# RK3399-AP register map
File version: 1
CPU: CA7 r0p1, little endian, MPU, FPU, I-cache, D-cache, VTOR, 4 interrupt priority bits, 0 interrupts
Registers are 32-bit, read-write, reset 0x0 unless marked. A register's access mark holds for its fields unless they carry their own. Offsets are from the block's base; [hi:lo] are bit positions.

## UART0
Base 0xFF180000
Same registers: UART1 0xFF190000, UART2 0xFF1A0000, UART3 0xFF1B0000, UART4 0xFF370000
0x00 UART_RBR — Receive Buffer Register
  [7:0] DATA_INPUT — Data byte received on the serial input port (sin) in UART mode, or the serial infrared input (sir_in) in infrared mode. The data in this register is valid only if the Data Ready (DR) bit in the Line Status Register (LCR) is set. If in non-FIFO mode (FIFO_MODE == NONE) or FIFOs are disabled (FCR[0] set to zero), the data in the RBR must be read before the next data arrives, otherwise it is overwritten, resulting in an over-run error. If in FIFO mode (FIFO_MODE != NONE) and FIFOs are enabled (FCR[0] set to one), this register accesses the head of the receive FIFO. If the receive FIFO is full and this register is not read before the next data character arrives, then the data already in the FIFO is preserved, but any incoming data are lost and an over-run error occurs.
0x00 UART_THR — Transmit Holding Register
  [7:0] DATA_OUTPUT — Data to be transmitted on the serial output port (sout) in UART mode or the serial infrared output (sir_out_n) in infrared mode. Data should only be written to the THR when the THR Empty (THRE) bit (LSR[5]) is set. If in non-FIFO mode or FIFOs are disabled (FCR[0] = 0) and THRE is set, writing a single character to the THR clears the THRE. Any additional writes to the THR before the THRE is set again causes the THR data to be overwritten. If in FIFO mode and FIFOs are enabled (FCR[0] = 1) and THRE is set, x number of characters of data may be written to the THR before the FIFO is full. The number x (default=16) is determined by the value of FIFO Depth that you set during configuration. Any attempt to write data when the FIFO is full results in the write data being lost.
0x00 UART_DLL — Divisor Latch (Low)
  [7:0] BAUD_RATE_DIVISOR_L — Lower 8-bits of a 16-bit, read/write, Divisor Latch register that contains the baud rate divisor for the UART. This register may only be accessed when the DLAB bit (LCR[7]) is set and the UART is not busy (USR[0] is zero). The output baud rate is equal to the serial clock (sclk) frequency divided by sixteen times the value of the baud rate divisor, as follows: baud rate = (serial clock freq) / (16 * divisor). Note that with the Divisor Latch Registers (DLL and DLH) set to zero, the baud clock is disabled and no serial communications occur. Also, once the DLH is set, at least 8 clock cycles of the slowest UART clock should be allowed to pass before transmitting or receiving data.
0x04 UART_DLH — Divisor Latch (High)
  [7:0] BAUD_RATE_DIVISOR_H — Upper 8 bits of a 16-bit, read/write, Divisor Latch register that contains the baud rate divisor for the UART.
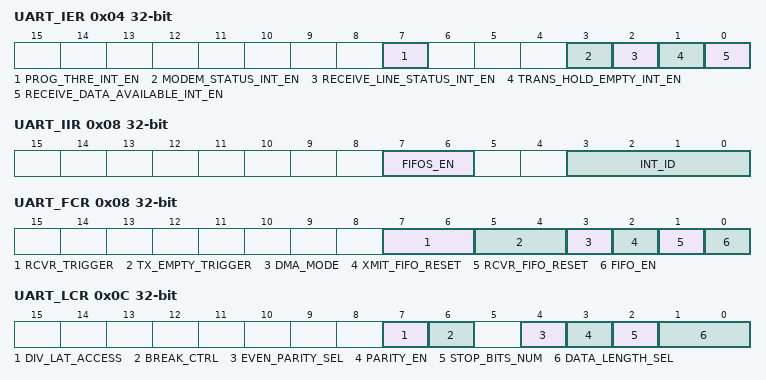
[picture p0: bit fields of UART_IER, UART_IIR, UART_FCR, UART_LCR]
0x04 UART_IER — Interrupt Enable Register
  [7] PROG_THRE_INT_EN — Programmable THRE Interrupt Mode Enable This is used to enable/disable the generation of THRE Interrupt. 0 = disabled 1 = enabled
  [3] MODEM_STATUS_INT_EN — Enable Modem Status Interrupt. This is used to enable/disable the generation of Modem Status Interrupt. This is the fourth highest priority interrupt. 0 = disabled 1 = enabled
  [2] RECEIVE_LINE_STATUS_INT_EN — Enable Receiver Line Status Interrupt. This is used to enable/disable the generation of Receiver Line Status Interrupt. This is the highest priority interrupt. 0 = disabled 1 = enabled
  [1] TRANS_HOLD_EMPTY_INT_EN — Enable Transmit Holding Register Empty Interrupt.
  [0] RECEIVE_DATA_AVAILABLE_INT_EN — Enable Received Data Available Interrupt. This is used to enable/disable the generation of Received Data Available Interrupt and the Character Timeout Interrupt (if in FIFO mode and FIFOs enabled). These are the second highest priority interrupts. 0 = disabled 1 = enabled
0x08 UART_IIR ro — Interrupt Identification Register
  [7:6] FIFOS_EN — FIFOs Enabled. This is used to indicate whether the FIFOs are enabled or disabled. 00 = disabled 11 = enabled
  [3:0] INT_ID — Interrupt ID This indicates the highest priority pending interrupt which can be one of the following types: 0000 = modem status 0001 = no interrupt pending 0010 = THR empty 0100 = received data available 0110 = receiver line status 0111 = busy detect 1100 = character timeout
0x08 UART_FCR wo — FIFO Control Register
  [7:6] RCVR_TRIGGER — RCVR Trigger. This is used to select the trigger level in the receiver FIFO at which the Received Data Available Interrupt is generated. In auto flow control mode it is used to determine when the rts_n signal is de-asserted. It also determines when the dma_rx_req_n signal is asserted in certain modes of operation. The following trigger levels are supported: 00 = 1 character in the FIFO 01 = FIFO 1/4 full 10 = FIFO 1/2 full 11 = FIFO 2 less than ful
  [5:4] TX_EMPTY_TRIGGER — TX Empty Trigger. This is used to select the empty threshold level at which the THRE Interrupts are generated when the mode is active. It also determines when the dma_tx_req_n signal is asserted when in certain modes of operation. The following trigger levels are supported: 00 = FIFO empty 01 = 2 characters in the FIFO 10 = FIFO 1/4 full 11 = FIFO 1/2 full
  [3] DMA_MODE — DMA Mode This determines the DMA signalling mode used for the dma_tx_req_n and dma_rx_req_n output signals when additional DMA handshaking signals are not selected . 0 = mode 0 1 = mode 11100 = character timeout.
  [2] XMIT_FIFO_RESET — XMIT FIFO Reset. This resets the control portion of the transmit FIFO and treats the FIFO as empty. This also de-asserts the DMA TX request and single signals when additional DMA handshaking signals are selected . Note that this bit is \'self-clearing\'. It is not necessary to clear this bit.
  [1] RCVR_FIFO_RESET — RCVR FIFO Reset. This resets the control portion of the receive FIFO and treats the FIFO as empty. This also de-asserts the DMA RX request and single signals when additional DMA handshaking signals are selected. Note that this bit is \'self-clearing\'. It is not necessary to clear this bit.
  [0] FIFO_EN — FIFO Enable. FIFO Enable. This enables/disables the transmit (XMIT) and receive (RCVR) FIFOs. Whenever the value of this bit is changed both the XMIT and RCVR controller portion of FIFOs is reset.
0x0C UART_LCR — Line Control Register
  [7] DIV_LAT_ACCESS — Divisor Latch Access Bit. Writeable only when UART is not busy (USR[0] is zero), always readable. This bit is used to enable reading and writing of the Divisor Latch register (DLL and DLH) to set the baud rate of the UART. This bit must be cleared after initial baud rate setup in order to access other registers.
  [6] BREAK_CTRL — Break Control Bit. This is used to cause a break condition to be transmitted to the receiving device. If set to one the serial output is forced to the spacing (logic 0) state. When not in Loopback Mode, as determined by MCR[4], the sout line is forced low until the Break bit is cleared. If MCR[6] set to one, the sir_out_n line is continuously pulsed. When in Loopback Mode, the break condition is internally looped back to the receiver and the sir_out_n line is forced low.
  [4] EVEN_PARITY_SEL — Even Parity Select. Writeable only when UART is not busy (USR[0] is zero), always readable. This is used to select between even and odd parity, when parity is enabled (PEN set to one). If set to one, an even number of logic 1s is transmitted or checked. If set to zero, an odd number of logic 1s is transmitted or checked.
  [3] PARITY_EN — Parity Enable. Writeable only when UART is not busy (USR[0] is zero), always readable. This bit is used to enable and disable parity generation and detection in transmitted and received serial character respectively. 0 = parity disabled 1 = parity enabled
  [2] STOP_BITS_NUM — Number of stop bits. Writeable only when UART is not busy (USR[0] is zero), always readable. This is used to select the number of stop bits per character that the peripheral transmits and receives. If set to zero, one stop bit is transmitted in the serial data. If set to one and the data bits are set to 5 (LCR[1:0] set to zero) one and a half stop bits is transmitted. Otherwise, two stop bits are transmitted. Note that regardless of the number of stop bits selected, the receiver checks only the first stop bit. 0 = 1 stop bit 1 = 1.5 stop bits when DLS (LCR[1:0]) is zero, else 2 stop bit.
  [1:0] DATA_LENGTH_SEL — Data Length Select. Writeable only when UART is not busy (USR[0] is zero), always readable. This is used to select the number of data bits per character that the peripheral transmits and receives. The number of bit that may be selected areas follows: 00 = 5 bits 01 = 6 bits 10 = 7 bits 11 = 8 bits
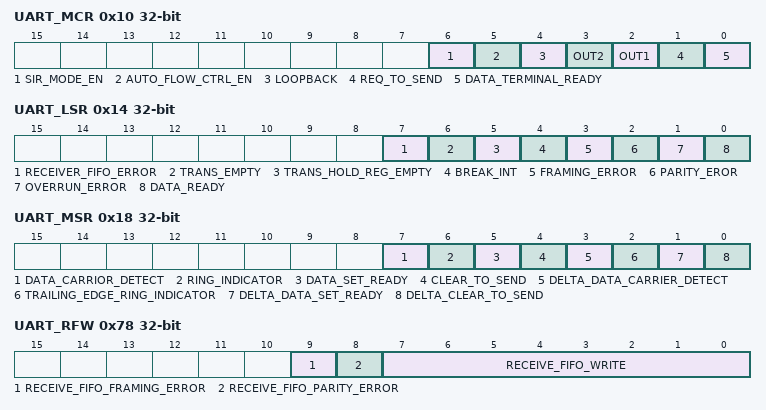
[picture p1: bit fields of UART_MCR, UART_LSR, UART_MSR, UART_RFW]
0x10 UART_MCR — Modem Control Register
  [6] SIR_MODE_EN — SIR Mode Enable. SIR Mode Enable. This is used to enable/disable the IrDA SIR Mode . 0 = IrDA SIR Mode disabled 1 = IrDA SIR Mode enabled
  [5] AUTO_FLOW_CTRL_EN — Auto Flow Control Enable. 0 = Auto Flow Control Mode disabled 1 = Auto Flow Control Mode enabled
  [4] LOOPBACK — LoopBack Bit. This is used to put the UART into a diagnostic mode for test purposes.
  [3] OUT2 — OUT2. This is used to directly control the user-designated Output2 (out2_n) output. The value written to this location is inverted and driven out on out2_n, that is: 0 = out2_n de-asserted (logic 1) 1 = out2_n asserted (logic 0)
  [2] OUT1 — OUT1 This is used to directly control the user-designated Output2 (out2_n) output. The value written to this location is inverted and driven out on out2_n, that is: 1’b0: out2_n de-asserted (logic 1) 1’b1: out2_n asserted (logic 0) req_to_send Request to Send. This is used to directly control the Request to Send (rts_n) output. The Request To Send (rts_n) output is used to inform the modem or data set that the UART is ready to exchange data.
  [1] REQ_TO_SEND — Request to Send. This is used to directly control the Request to Send (rts_n) output. The Request To Send (rts_n) output is used to inform the modem or data set that the UART is ready to exchange data.
  [0] DATA_TERMINAL_READY — Data Terminal Ready. This is used to directly control the Data Terminal Ready (dtr_n) output. The value written to this location is inverted and driven out on dtr_n, that is: 0 = dtr_n de-asserted (logic 1) 1 = dtr_n asserted (logic 0)
0x14 UART_LSR ro — Line Status Register
  [7] RECEIVER_FIFO_ERROR — Receiver FIFO Error bit. This bit is relevant FIFOs are enabled (FCR[0] set to one). This is used to indicate if there is at least one parity error, framing error, or break indication in the FIFO. 0 = no error in RX FIFO 1 = error in RX FIFO
  [6] TRANS_EMPTY — Transmitter Empty bit. Transmitter Empty bit. If FIFOs enabled (FCR[0] set to one), this bit is set whenever the Transmitter Shift Register and the FIFO are both empty. If FIFOs are disabled, this bit is set whenever the Transmitter Holding Register and the Transmitter Shift Register are both empty.
  [5] TRANS_HOLD_REG_EMPTY — Transmit Holding Register Empty bit. If THRE mode is disabled (IER[7] set to zero) and regardless of FIFO\'s being implemented/enabled or not, this bit indicates that the THR or TX FIFO is empty. This bit is set whenever data is transferred from the THR or TX FIFO to the transmitter shift register and no new data has been written to the THR or TX FIFO. This also causes a THRE Interrupt to occur, if the THRE Interrupt is enabled. If IER[7] set to one and FCR[0] set to one respectively, the functionality is switched to indicate the transmitter FIFO is full, and no longer controls THRE interrupts, which are then controlled by the FCR[5:4] threshold setting.
  [4] BREAK_INT — Break Interrupt bit. This is used to indicate the detection of a break sequence on the serial input data.
  [3] FRAMING_ERROR — Framing Error bit. This is used to indicate the occurrence of a framing error in the receiver. A framing error occurs when the receiver does not detect a valid STOP bit in the received data.
  [2] PARITY_EROR — Parity Error bit. This is used to indicate the occurrence of a parity error in the receiver if the Parity Enable (PEN) bit (LCR[3]) is set.
  [1] OVERRUN_ERROR — Overrun error bit. This is used to indicate the occurrence of an overrun error. This occurs if a new data character was received before the previous data was read.
  [0] DATA_READY — Data Ready bit. This is used to indicate that the receiver contains at least one character in the RBR or the receiver FIFO. 0 = no data ready 1 = data ready
0x18 UART_MSR ro — Modem Status Register
  [7] DATA_CARRIOR_DETECT — Data Carrier Detect. This is used to indicate the current state of the modem control line dcd_n.
  [6] RING_INDICATOR — Ring Indicator. This is used to indicate the current state of the modem control line ri_n.
  [5] DATA_SET_READY — Data Set Ready. This is used to indicate the current state of the modem control line dsr_n.
  [4] CLEAR_TO_SEND — Clear to Send. This is used to indicate the current state of the modem control line cts_n.
  [3] DELTA_DATA_CARRIER_DETECT — Delta Data Carrier Detect. This is used to indicate that the modem control line dcd_n has changed since the last time the MSR was read.
  [2] TRAILING_EDGE_RING_INDICATOR — Trailing Edge of Ring Indicator. Trailing Edge of Ring Indicator. This is used to indicate that a change on the input ri_n (from an active-low to an inactive-high state) has occurred since the last time the MSR was read.
  [1] DELTA_DATA_SET_READY — Delta Data Set Ready. This is used to indicate that the modem control line dsr_n has changed since the last time the MSR was read.
  [0] DELTA_CLEAR_TO_SEND — Delta Clear to Send. This is used to indicate that the modem control line cts_n has changed since the last time the MSR was read.
0x1C UART_SCR — Scratchpad Register
  [7:0] TEMP_STORE_SPACE — This register is for programmers to use as a temporary storage space.
0x30 UART_SRBR ro — Shadow Receive Buffer Register
  [7:0] SHADOW_RBR — This is a shadow register for the RBR and has been allocated sixteen 32-bit locations so as to accommodate burst accesses from the master. This register contains the data byte received on the serial input port (sin) in UART mode or the serial infrared input (sir_in) in infrared mode. The data in this register is valid only if the Data Ready (DR) bit in the Line status Register (LSR) is set. If FIFOs are disabled (FCR[0] set to zero), the data in the RBR must be read before the next data arrives, otherwise it is overwritten, resulting in an overrun error. If FIFOs are enabled (FCR[0] set to one), this register accesses the head of the receive FIFO. If the receive FIFO is full and this register is not read before the next data character arrives, then the data already in the FIFO are preserved, but any incoming data is lost. An overrun error also occurs.
0x6C UART_STHR ro — Shadow Transmit Holding Register
  [7:0] SHADOW_THR — This is a shadow register for the THR.
0x70 UART_FAR — FIFO Access Register
  [0] FIFO_ACCESS_TEST_EN — This register is use to enable a FIFO access mode for testing, so that the receive FIFO can be written by the master and the transmit FIFO can be read by the master when FIFOs are implemented and enabled. When FIFOs are not enabled it allows the RBR to be written by the master and the THR to be read by the master. 0 = FIFO access mode disabled 1 = FIFO access mode enabled
0x74 UART_TFR ro — Transmit FIFO Read
  [7:0] TRANS_FIFO_READ — Transmit FIFO Read. These bits are only valid when FIFO access mode is enabled (FAR[0] is set to one).When FIFOs are implemented and enabled, reading this register gives the data at the top of the transmit FIFO. Each consecutive read pops the transmit FIFO and gives the next data value that is currently at the top of the FIFO.
0x78 UART_RFW wo — Receive FIFO Write
  [9] RECEIVE_FIFO_FRAMING_ERROR — Receive FIFO Framing Error. These bits are only valid when FIFO access mode is enabled (FAR[0] is set to one).
  [8] RECEIVE_FIFO_PARITY_ERROR — Receive FIFO Parity Error. These bits are only valid when FIFO access mode is enabled (FAR[0] is set to one).
  [7:0] RECEIVE_FIFO_WRITE — Receive FIFO Write Data. These bits are only valid when FIFO access mode is enabled (FAR[0] is set to one). When FIFOs are enabled, the data that is written to the RFWD is pushed into the receive FIFO. Each consecutive write pushes the new data to the next write location in the receive FIFO. When FIFOs not enabled, the data that is written to the RFWD is pushed into the RBR.
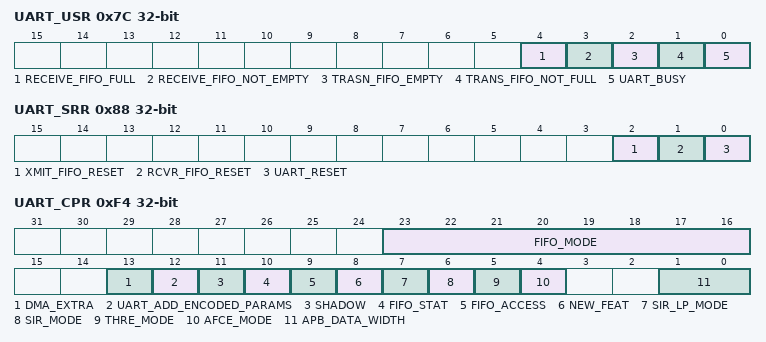
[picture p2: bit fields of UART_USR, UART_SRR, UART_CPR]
0x7C UART_USR ro — UART Status Register
  [4] RECEIVE_FIFO_FULL — Receive FIFO Full. This is used to indicate that the receive FIFO is completely full. 0 = Receive FIFO not full 1 = Receive FIFO Full This bit is cleared when the RX FIFO is no longer full.
  [3] RECEIVE_FIFO_NOT_EMPTY — Receive FIFO Not Empty. This is used to indicate that the receive FIFO contains one or more entries. 0 = Receive FIFO is empty 1 = Receive FIFO is not empty This bit is cleared when the RX FIFO is empty.
  [2] TRASN_FIFO_EMPTY — Transmit FIFO Empty. This is used to indicate that the transmit FIFO is completely empty. 0 = Transmit FIFO is not empty 1 = Transmit FIFO is empty This bit is cleared when the TX FIFO is no longer empty
  [1] TRANS_FIFO_NOT_FULL — Transmit FIFO Not Full. This is used to indicate that the transmit FIFO in not full. 0 = Transmit FIFO is full 1 = Transmit FIFO is not full This bit is cleared when the TX FIFO is full.
  [0] UART_BUSY — UART Busy. UART Busy. This is indicates that a serial transfer is in progress, when cleared indicates that the UART is idle or inactive. 0 = UART is idle or inactive 1 = UART is busy (actively transferring data)
0x80 UART_TFL — Transmit FIFO Level
  [4:0] TRANS_FIFO_LEVEL — Transmit FIFO Level. This is indicates the number of data entries in the transmit FIFO.
0x84 UART_RFL ro — Receive FIFO Level
  [4:0] RECEIVE_FIFO_LEVEL — Receive FIFO Level. This is indicates the number of data entries in the receive FIFO.
0x88 UART_SRR wo — Software Reset Register
  [2] XMIT_FIFO_RESET — XMIT FIFO Reset. This is a shadow register for the XMIT FIFO Reset bit (FCR[2]).
  [1] RCVR_FIFO_RESET — RCVR FIFO Reset. This is a shadow register for the RCVR FIFO Reset bit (FCR[1]).
  [0] UART_RESET — UART Reset. This asynchronously resets the UART and synchronously removes the reset assertion. For a two clock implementation both pclk and sclk domains are reset.
0x8C UART_SRTS — Shadow Request to Send
  [0] SHADOW_REQ_TO_SEND — Shadow Request to Send. This is a shadow register for the RTS bit (MCR[1]), this can be used to remove the burden of having to performing a read- modify-write on the MCR.
0x90 UART_SBCR — Shadow Break Control Register
  [0] SHADOW_BREAK_CTRL — Shadow Break Control Bit. This is a shadow register for the Break bit (LCR[6]), this can be used to remove the burden of having to performing a read modify write on the LCR.
0x94 UART_SDMAM — Shadow DMA Mode
  [0] SHADOW_DMA_MODE — Shadow DMA Mode. This is a shadow register for the DMA mode bit (FCR[3]).
0x98 UART_SFE — Shadow FIFO Enable
  [0] SHADOW_FIFO_EN — Shadow FIFO Enable. Shadow FIFO Enable. This is a shadow register for the FIFO enable bit (FCR[0]).
0x9C UART_SRT — Shadow RCVR Trigger
  [0] SHADOW_RCVR_TRIGGER — Shadow RCVR Trigger. This is a shadow register for the RCVR trigger bits (FCR[7:6]).
0xA0 UART_STET — Shadow TX Empty Trigger
  [0] SHADOW_TX_EMPTY_TRIGGER — Shadow TX Empty Trigger. This is a shadow register for the TX empty trigger bits (FCR[5:4]).
0xA4 UART_HTX — Halt TX
  [0] HALT_TX_EN — This register is use to halt transmissions for testing, so that the transmit FIFO can be filled by the master when FIFOs are implemented and enabled. 0 = Halt TX disabled 1 = Halt TX enabled
0xA8 UART_DMASA wo — DMA Software Acknowledge
  [0] DMA_SOFTWARE_ACK — This register is use to perform a DMA software acknowledge if a transfer needs to be terminated due to an error condition.
0xF4 UART_CPR ro — Component Parameter Register Component Parameter Register UART_CPR is UART0’s own unique register
  [23:16] FIFO_MODE — 0x00 = 0 0x01 = 16 0x02 = 32 to 0x80 = 2048 0x81- 0xff = reserved
  [13] DMA_EXTRA — 0 = FALSE 1 = TRUE
  [12] UART_ADD_ENCODED_PARAMS — 0 = FALSE 1 = TRUE
  [11] SHADOW — 0 = FALSE 1 = TRUE
  [10] FIFO_STAT — 0 = FALSE 1 = TRUE
  [9] FIFO_ACCESS — 0 = FALSE 1 = TRUE
  [8] NEW_FEAT — 0 = FALSE 1 = TRUE
  [7] SIR_LP_MODE — 0 = FALSE 1 = TRUE
  [6] SIR_MODE — 0 = FALSE 1 = TRUE
  [5] THRE_MODE — 0 = FALSE 1 = TRUE
  [4] AFCE_MODE — 0 = FALSE 1 = TRUE
  [1:0] APB_DATA_WIDTH — 00 = 8 bits 01 = 16 bits 10 = 32 bits 11 = reserved
0xF8 UART_UCV ro reset 0x330372A — UART Component Version
  [31:0] VER — ASCII value for each number in the version
0xFC UART_CTR ro reset 0x44570110 — Component Type Register
  [31:0] PERIPHERAL_ID — This register contains the peripherals identification code.
